# RA2A1 register map
Vendor: Renesas Electronics Corporation; Series: RA2; File version: 1.1
CPU: other r1p0, little endian, MPU, no FPU, VTOR, 2 interrupt priority bits
Registers are 8-bit, read-write, reset 0x0 unless marked. A register's access mark holds for its fields unless they carry their own. Offsets are from the block's base; [hi:lo] are bit positions; {n}, {i} and the like mark numbered series; 'fields as' and 'values as' point back to an identical list.

## SDADC24 — 24-Bit Sigma-Delta A/D Converter
Base 0x4009C000
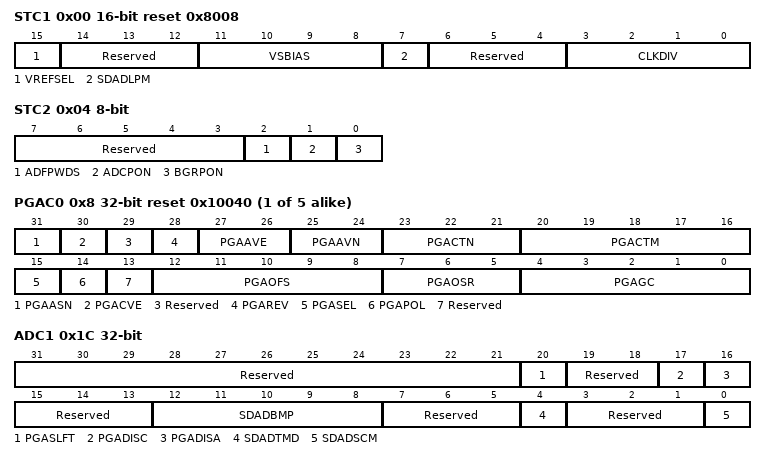
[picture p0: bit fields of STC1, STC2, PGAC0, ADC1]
0x00 STC1 16-bit reset 0x8008 — Startup Control Register 1
  [15] VREFSEL — VREF mode select
    0=Internal VREF mode; 1=External VREF mode
  [14:12] Reserved — These bits are read as 000. The write value should be 000.
  [11:8] VSBIAS — Reference voltage select
    0=0.8 V; 1=1.0 V; 2=1.2 V; 3=1.4 V; 4=1.6 V; 5=1.8 V; 6=2.0 V; 7=2.2 V; 15=2.4 V (This voltage can be set only if VREFSEL = 1. When VREFSEL = 0, 2.2 V is set (rather than 2.4 V)); other=others (Settings are prohibited.)
  [7] SDADLPM — A/D conversion operation mode select
    0=Normal A/D conversion mode: SDADC24 reference clock:4 MHz, Oversampling clock:1 MHz; 1=Low-power A/D conversion mode(1/8 of the clock in normal A/D conversion mode): SDADC24 reference clock:500 kHz,Oversampling clock: 125 kHz
  [6:4] Reserved — These bits are read as 000. The write value should be 000.
  [3:0] CLKDIV — SDADC24 reference clock division select
    0=SDADCCLK (no division); {v}=SDADCCLK/{v+1} (1/{v+1}) (v=1..5); 6=SDADCCLK/8 (1/8); 7=SDADCCLK/12 (1/12); 8=SDADCCLK/16 (1/16); other=others (Settings are prohibited.)
0x04 STC2 — Startup Control Register 2
  [7:3] Reserved — These bits are read as 00000. The write value should be 00000.
  [2] ADFPWDS — ADREG forced power-down mode
    0=Power of ADREG is controlled by the BGRPON setting; 1=Power of only ADREG is turned off regardless of the BGRPON setting
  [1] ADCPON — ADC reference supply part power control
    0=Turn off the power of VBIAS, PGA and sigma-delta A/D converter; 1=Turn on the power of VBIAS, PGA and sigma-delta A/D converter
  [0] BGRPON — BGR part power control
    0=Turn off the power of ADBGR, SBIAS/VREFI, and ADREG; 1=Turn on the power of ADBGR, SBIAS/VREFI, and ADREG
{0x8+4i} PGAC{i} (i=0..4) 32-bit reset 0x10040 — Input Multiplexer {i} Setting Register
  [31] PGAASN — Selection of the mode for specifying the number of A/D conversions in ADSCAN
    0=Specify 1 to 8,032 times by using the value set in the PGACTN[2:0] and PGACTM[4:0] bits; 1=Specify 1 to 255 times linearly by using the value set in the PGACTN[2:0] and PGACTM[4:0] bits
  [30] PGACVE — Calibration enable
    0=Do not calculate the calibration correction factor; 1=Calculate the calibration correction factor
  [29] Reserved — This bit is read as 0. The write value should be 0.
  [28] PGAREV — Single-End Input A/D Converted Data Inversion Select
    0=Do not invert the conversion result data; 1=Invert the conversion result data
  [27:26] PGAAVE — Selection of averaging processing
    0=Do not average the A/D conversion results; 1=Do not average the A/D conversion results; 2=Average the A/D conversion results and generates SDADC_ADI each time an A/D conversion occurs; 3=Perform averaging, and generate SDADC_ADI at each time of average value output (A/D conversion is performed N times)
  [25:24] PGAAVN — Selection of the number of data to be averaged
    0=8; 1=16; 2=32; 3=64
  [23:21] PGACTN — Coefficient (n) selection of the A/D conversion count (N) in AUTOSCAN
    {v}={v} (v=0..7)
  [20:16] PGACTM — Coefficient (m) selection of the A/D conversion count (N) in AUTOSCAN
  [15] PGASEL — Analog Channel Input Mode Select
    0=Differential input mode; 1=Single-end input mode
  [14] PGAPOL — Polarity select
    0=Positive-side single-end input; 1=Negative-side single-end input
  [13] Reserved — This bit is read as 0. The write value should be 0.
  [12:8] PGAOFS — Offset voltage select
  [7:5] PGAOSR — Oversampling ratio select
    0=64; 1=128; 2=256; 3=512; 4=1024; 5=2048; other=others (Settings are prohibited.)
  [4:0] PGAGC — Gain selection of a programmable gain instrumentation amplifier ( Gset1, Gset2, Gtotal )
    0=(1, 1, 1); 4=(2, 1, 2); 8=(3, 1, 3); 12=(4, 1, 4); 16=(8, 1, 8); 1=(1, 2, 2); 5=(2, 2, 4); 9=(3, 2, 6); 13=(4, 2, 8); 17=(8, 2, 16); 2=(1, 4, 4); 6=(2, 4, 8); 10=(3, 4, 12); 14=(4, 4, 16); 18=(8, 4, 32); 3=(1, 8, 8); 7=(2, 8, 16); 11=(3, 8, 24); 15=(4, 8, 32); other=others (Settings are prohibited.)
0x1C ADC1 32-bit — Sigma-delta A/D Converter Control Register 1
  [31:21] Reserved — These bits are read as 00000000000. The write value should be 00000000000.
  [20] PGASLFT — PGA offset self-diagnosis enable
    0=Disable PGA offset self-diagnosis; 1=Enable PGA offset self-diagnosis
  [19:18] Reserved — These bits are read as 00. The write value should be 00.
  [17] PGADISC — Disconnection Detection Assist Setting
    0=Discharge; 1=Pre-charge
  [16] PGADISA — Control of disconnection detection
    0=Normal operation; 1=State of disconnection detection
  [15:13] Reserved — These bits are read as 000. The write value should be 000.
  [12:8] SDADBMP — A/D conversion control of the signal from input multiplexer
  [7:5] Reserved — These bits are read as 000. The write value should be 000.
  [4] SDADTMD — Selection of A/D conversion trigger signal
    0=Software trigger (conversion is started by a write to SFR); 1=Hardware trigger (conversion is started in synchronization with the event signal selected by ELC_SDADC24)
  [3:1] Reserved — These bits are read as 000. The write value should be 000.
  [0] SDADSCM — Selection of autoscan mode
    0=Continuous scan mode; 1=Single scan mode
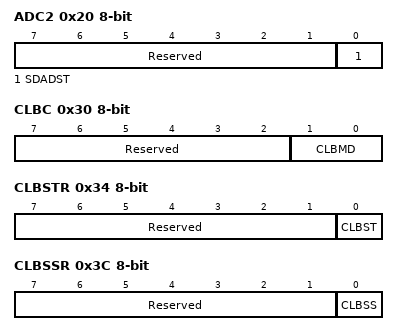
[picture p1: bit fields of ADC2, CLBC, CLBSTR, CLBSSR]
0x20 ADC2 — Sigma-delta A/D Converter Control Register 2
  [7:1] Reserved — These bits are read as 0000000. The write value should be 0000000.
  [0] SDADST — Control of A/D conversion
    0=Stop A/D conversion; 1=Start A/D conversion
0x24 ADCR 32-bit — Sigma-delta A/D Converter Conversion Result Register
  [31:28] Reserved — These bits are read as 0000. The write value should be 0000.
  [27:25] SDADCRC ro — Channel number for an A/D conversion result
    0=Reset value (Conversion result is invalid); {v}=Input multiplexer {v-1} (ANSD{v-1}P / ANSD{v-1}N) (v=1..4); 5=Input multiplexer 4 (AMP0O / AMP1O)
  [24] SDADCRS ro — Status of an A/D conversion result
    0=Normal status (within the range); 1=Overflow occurred
  [23:0] SDADCRD ro — The 24-bit A/D conversion result
  [15:0] Reserved — These bits are read as 0000000000000000. The write value should be 0000000000000000.
0x28 ADAR 32-bit ro — Sigma-delta A/D Converter Average Value Register
  [31:28] Reserved — These bits are read as 0000.
  [27:25] SDADMVC — Channel number for an A/D conversion result
    values as ADCR.SDADCRC
  [24] SDADMVS — Status of an A/D conversion result
    0=Normal status (within the range); 1=Overflow occurred
  [23:0] SDADMVD — The 24-bit A/D average value
  [15:0] Reserved — These bits are read as 0000000000000000.
0x30 CLBC — Calibration Control Register
  [7:2] Reserved — These bits are read as 000000. The write value should be 000000.
  [1:0] CLBMD — These bits are read as 0. The write value should be 0.
    0=Internal calibration mode; 1=External offset calibration mode; 2=External gain calibration mode; 3=Settings are prohibited
0x34 CLBSTR — Calibration Start Control Register
  [7:1] Reserved — These bits are read as 0000000. The write value should be 0000000.
  [0] CLBST — Calibration start control
    0=Disable writing; 1=Start calibration
0x3C CLBSSR ro — Calibration Status Register
  [7:1] Reserved — These bits are read as 0000000.
  [0] CLBSS — Calibration status
    0=Calibration is not running; 1=Calibration is running
